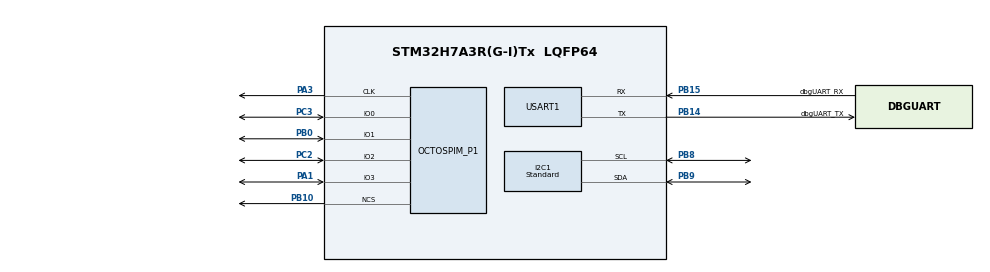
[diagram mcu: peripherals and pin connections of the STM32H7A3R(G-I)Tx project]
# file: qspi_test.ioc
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CORTEX_M7.default_mode_Activation=0
I2C1.Analog_Filter=I2C_ANALOGFILTER_DISABLE
I2C1.CustomTiming=Enabled
I2C1.I2C_Coeff_DF=10
I2C1.I2C_Fall_Time=300
I2C1.I2C_Rise_Time=1000
I2C1.I2C_Speed_Mode=I2C_Standard
I2C1.Speed=50
I2C1.Timing=0x40F135B4
Mcu.Family=STM32H7
Mcu.Name=STM32H7A3R(G-I)Tx
Mcu.Package=LQFP64
NVIC.PriorityGroup=NVIC_PRIORITYGROUP_4
OCTOSPI1.ChipSelectHighTime=1
OCTOSPI1.ClockPrescaler=2
OCTOSPI1.DelayBlockBypass=HAL_OSPI_DELAY_BLOCK_BYPASSED
OCTOSPI1.DeviceSize=27
OCTOSPI1.DeviceType=SPI_DEVICE_0
OCTOSPI1.FifoThreshold=4
OCTOSPI1.MemoryType=HAL_OSPI_MEMTYPE_MICRON
OCTOSPI1.Refresh=0
OCTOSPI1.SampleShifting=HAL_OSPI_SAMPLE_SHIFTING_HALFCYCLE
PA1.Mode=OCTOSPI1_IOL_Port1L
PA1.Signal=OCTOSPIM_P1_IO3
PA13.Mode=Trace_Asynchronous_SW
PA13.Signal=DEBUG_JTMS-SWDIO
PA14.Mode=Trace_Asynchronous_SW
PA14.Signal=DEBUG_JTCK-SWCLK
PA3.Mode=O1_P1_CLK
PA3.Signal=OCTOSPIM_P1_CLK
PB0.Mode=OCTOSPI1_IOL_Port1L
PB0.Signal=OCTOSPIM_P1_IO1
PB10.Mode=OCTOSPI1_Port1_NCS
PB10.Signal=OCTOSPIM_P1_NCS
PB14.GPIO_Label=dbgUART_TX
PB14.Mode=Asynchronous
PB14.Signal=USART1_TX
PB15.GPIO_Label=dbgUART_RX
PB15.Mode=Asynchronous
PB15.Signal=USART1_RX
PB3.Mode=Trace_Asynchronous_SW
PB3.Signal=DEBUG_JTDO-SWO
PB8.Mode=I2C
PB8.Signal=I2C1_SCL
PB9.Mode=I2C
PB9.Signal=I2C1_SDA
PC2.Mode=OCTOSPI1_IOL_Port1L
PC2.Signal=OCTOSPIM_P1_IO2
PC3.Mode=OCTOSPI1_IOL_Port1L
PC3.Signal=OCTOSPIM_P1_IO0
ProjectManager.HeapSize=0x200
ProjectManager.StackSize=0x400
ProjectManager.TargetToolchain=STM32CubeIDE
RCC.ADCFreq_Value=129000000
RCC.APB1Freq_Value=140000000
RCC.APB2Freq_Value=140000000
RCC.APB3Freq_Value=140000000
RCC.APB4Freq_Value=140000000
RCC.CDPPRE=RCC_APB3_DIV2
RCC.CDPPRE1=RCC_APB1_DIV2
RCC.CDPPRE2=RCC_APB2_DIV2
RCC.CortexFreq_Value=280000000
RCC.DIVM1=4
RCC.DIVN1=35
RCC.HCLKFreq_Value=280000000
RCC.HSE_VALUE=8000000
RCC.I2C123CLockSelection=RCC_I2C123CLKSOURCE_HSI
RCC.PLL2FRACN=0
RCC.PLL3FRACN=0
RCC.PLLFRACN=0
RCC.QSPICLockSelection=RCC_OSPICLKSOURCE_PLL
RCC.SRDPPRE=RCC_APB4_DIV2
RCC.SYSCLKFreq_VALUE=280000000
RCC.SYSCLKSource=RCC_SYSCLKSOURCE_PLLCLK
RCC.USBFreq_Value=280000000
USART1.VirtualMode-Asynchronous=VM_ASYNC
VP_OCTOSPI1_VS_quad.Mode=quad_mode
board=custom

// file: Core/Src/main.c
/* USER CODE BEGIN Header */
/**
  ******************************************************************************
  * @file           : main.c
  * @brief          : Main program body
  ******************************************************************************
  * @attention
  *
  * Copyright (c) 2024 STMicroelectronics.
  * All rights reserved.
  *
  * This software is licensed under terms that can be found in the LICENSE file
  * in the root directory of this software component.
  * If no LICENSE file comes with this software, it is provided AS-IS.
  *
  ******************************************************************************
  */
/* USER CODE END Header */
#include "main.h"
#include "i2c.h"
#include "octospi.h"
#include "usart.h"
#include "gpio.h"

/* USER CODE BEGIN Includes */
#include "string.h"
/* USER CODE END Includes */

void SystemClock_Config(void);

/* USER CODE BEGIN 0 */
/*W25Q32 memory parameters*/

uint8_t writebuf[] = "Hello world from QSPI";
uint8_t Readbuf[100];

/**************************************************************************/
/*!
    @brief  Configure OCTO-SPI as Memory Mapped Mode.
            Winbond W25Q128JVSIQ specific setting.
            * Address size is 24bit(16MBytes).
            * Initially sets QUAD-MODE(not need quadmode command).
            * MAX 133MHz CLK.
            * Support "XIP",thus suitable for MemoryMappedMode.
    @param  None.
    @retval None.
*/
/**************************************************************************/

/* USER CODE END 0 */

int main(void)
{

  /* MCU Configuration--------------------------------------------------------*/

  /* Reset of all peripherals, Initializes the Flash interface and the Systick. */
  HAL_Init();

  /* Configure the system clock */
  SystemClock_Config();

  /* Initialize all configured peripherals */
  MX_GPIO_Init();
  MX_USART1_UART_Init();
  MX_OCTOSPI1_Init();
  MX_I2C1_Init();
  /* USER CODE BEGIN 2 */

//		  HAL_StatusTypeDef ret;
//		  uint8_t rxbuf[100];
//		  uint8_t txbuf[] = "TEST";
//		  ret=W25Q128_OCTO_SPI_Init(&hospi1);
//
//		  //ret=W25Q128_OSPI_Erase_Chip(&hospi1);
//		  printf("Erased\r\n");
//		  //ret=W25Q128_OSPI_Write(&hospi1,txbuf,0x7FFFFEC/*0x3FFFFEC*/,sizeof(txbuf));
//		  ret=W25Q128_OSPI_Read(&hospi1, rxbuf,0x7FFFFEC,sizeof(txbuf));
//		  ret=W25Q128_OSPI_EnableMemoryMappedMode(&hospi1);
//		  HAL_Delay(1000);
//
//		  /*__IO*/ uint8_t *mem_addr;
//		  //mem_addr = (uint8_t *)(0x08010000);
//		  mem_addr = (uint8_t *)(0x090000000+0x7FFFFEC);
//		  uint8_t* ala = mem_addr;
//		  memcpy(rxbuf, mem_addr, sizeof(txbuf));

  //HAL_Delay(0x8ff);
  printf("Hello world!!!\r\n");
  char receiveData[8];
  memset(receiveData[0],0xff,8);
  HAL_StatusTypeDef result;				//1000100
  //result= HAL_I2C_IsDeviceReady(&hi2c1, 0b1010010<<1, 13, HAL_MAX_DELAY);
  result= HAL_I2C_IsDeviceReady(&hi2c1, /*0b1000100<<1*/0x3C<<1, 13, HAL_MAX_DELAY);
  //result=HAL_I2C_Mem_Read(&hi2c1, 0b1010010<<1, 0x00, 1,(uint8_t *) &receiveData,1, HAL_MAX_DELAY);
  //result= HAL_I2C_Master_Receive(&hi2c1, 0x3C<<1, (uint8_t *)&receiveData, 8, HAL_MAX_DELAY);
  //result= HAL_I2C_Master_Receive(&hi2c4, 0xA0, receiveData, 8, HAL_MAX_DELAY);
 // printf("%s\r\n", map[0]);
  HAL_Delay(0x1ff);
  /* USER CODE END 2 */

  /* Infinite loop */
  while (1)
  {

  }
}

void SystemClock_Config(void)
{
  RCC_OscInitTypeDef RCC_OscInitStruct = {0};
  RCC_ClkInitTypeDef RCC_ClkInitStruct = {0};

  /*AXI clock gating */
  RCC->CKGAENR = 0xFFFFFFFF;

  /** Supply configuration update enable
  */
  HAL_PWREx_ConfigSupply(PWR_LDO_SUPPLY);

  /** Configure the main internal regulator output voltage
  */
  __HAL_PWR_VOLTAGESCALING_CONFIG(PWR_REGULATOR_VOLTAGE_SCALE0);

  while(!__HAL_PWR_GET_FLAG(PWR_FLAG_VOSRDY)) {}

  /** Initializes the RCC Oscillators according to the specified parameters
  * in the RCC_OscInitTypeDef structure.
  */
  RCC_OscInitStruct.OscillatorType = RCC_OSCILLATORTYPE_HSI;
  RCC_OscInitStruct.HSIState = RCC_HSI_DIV1;
  RCC_OscInitStruct.HSICalibrationValue = 64;
  RCC_OscInitStruct.PLL.PLLState = RCC_PLL_ON;
  RCC_OscInitStruct.PLL.PLLSource = RCC_PLLSOURCE_HSI;
  RCC_OscInitStruct.PLL.PLLM = 4;
  RCC_OscInitStruct.PLL.PLLN = 35;
  RCC_OscInitStruct.PLL.PLLP = 2;
  RCC_OscInitStruct.PLL.PLLQ = 2;
  RCC_OscInitStruct.PLL.PLLR = 2;
  RCC_OscInitStruct.PLL.PLLRGE = RCC_PLL1VCIRANGE_3;
  RCC_OscInitStruct.PLL.PLLVCOSEL = RCC_PLL1VCOWIDE;
  RCC_OscInitStruct.PLL.PLLFRACN = 0;
  if (HAL_RCC_OscConfig(&RCC_OscInitStruct) != HAL_OK)
  {
    Error_Handler();
  }

  /** Initializes the CPU, AHB and APB buses clocks
  */
  RCC_ClkInitStruct.ClockType = RCC_CLOCKTYPE_HCLK|RCC_CLOCKTYPE_SYSCLK
                              |RCC_CLOCKTYPE_PCLK1|RCC_CLOCKTYPE_PCLK2
                              |RCC_CLOCKTYPE_D3PCLK1|RCC_CLOCKTYPE_D1PCLK1;
  RCC_ClkInitStruct.SYSCLKSource = RCC_SYSCLKSOURCE_PLLCLK;
  RCC_ClkInitStruct.SYSCLKDivider = RCC_SYSCLK_DIV1;
  RCC_ClkInitStruct.AHBCLKDivider = RCC_HCLK_DIV1;
  RCC_ClkInitStruct.APB3CLKDivider = RCC_APB3_DIV2;
  RCC_ClkInitStruct.APB1CLKDivider = RCC_APB1_DIV2;
  RCC_ClkInitStruct.APB2CLKDivider = RCC_APB2_DIV2;
  RCC_ClkInitStruct.APB4CLKDivider = RCC_APB4_DIV2;

  if (HAL_RCC_ClockConfig(&RCC_ClkInitStruct, FLASH_LATENCY_6) != HAL_OK)
  {
    Error_Handler();
  }
}

void Error_Handler(void)
{
  __disable_irq();
  while (1)
  {
  }
}
